# RockChip_RK3588 register map
Vendor: RockChip Electronics Co., Ltd.; Series: RK3588; File version: 0.1
Registers are 32-bit, read-write, no defined reset value unless marked. A register's access mark holds for its fields unless they carry their own. Offsets are from the block's base; [hi:lo] are bit positions; {n}, {i} and the like mark numbered series.

## IOC_EMMC
Base 0xFD5FD000
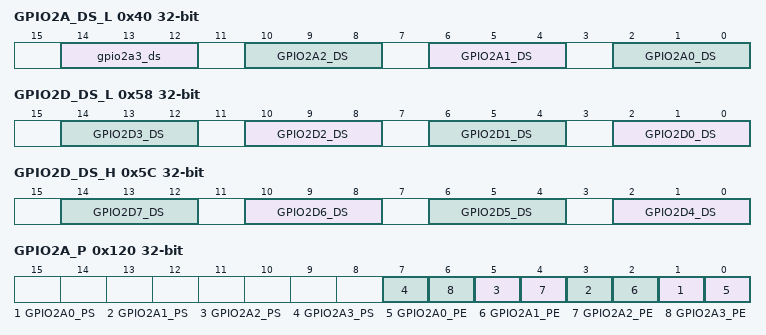
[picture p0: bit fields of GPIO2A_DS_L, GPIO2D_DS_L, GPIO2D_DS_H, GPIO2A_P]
0x40 GPIO2A_DS_L — GPIO2A Driver Strength Control Low bits
  [all] fields
    0=100OHM; 4=66OHM; 2=50OHM; 6=40OHM; 1=33OHM; 5=25OHM
  [14:12] gpio2a3_ds — GPIO2A3 DS control Driver Strength Selection
  [10:8] GPIO2A2_DS — GPIO2A2 DS control Driver Strength Selection
  [6:4] GPIO2A1_DS — GPIO2A1 DS control Driver Strength Selection
  [2:0] GPIO2A0_DS — GPIO2A0 DS control Driver Strength Selection
0x58 GPIO2D_DS_L — GPIO2D Driver Strength Control Low bits
  [all] fields
    0=100OHM; 4=66OHM; 2=50OHM; 6=40OHM; 1=33OHM; 5=25OHM
  [4n+2:4n] GPIO2D{n}_DS (n=0..3) — GPIO2D{n} DS control Driver Strength Selection
0x5C GPIO2D_DS_H — GPIO2D Driver Strength Control High bits
  [all] fields
    0=100OHM; 4=66OHM; 2=50OHM; 6=40OHM; 1=33OHM; 5=25OHM
  [4n-14:4n-16] GPIO2D{n}_DS (n=4..7) — GPIO2D{n} DS control Driver Strength Selection
0x120 GPIO2A_P — GPIO2A Pull-up/down Control
  [2n+1] GPIO2A{n}_PS (n=0..3) — GPIO2A{n} PS control Weak PU/PD Resistor Selection
    0=PD_SELECTION; 1=PU_SELECTION
  [2n] GPIO2A{n}_PE (n=0..3) — GPIO2A{n} PE control Active High Weak PU/PD Resistor Enable
    0=PU_PD_DISABLE; 1=PU_PD_ENABLE
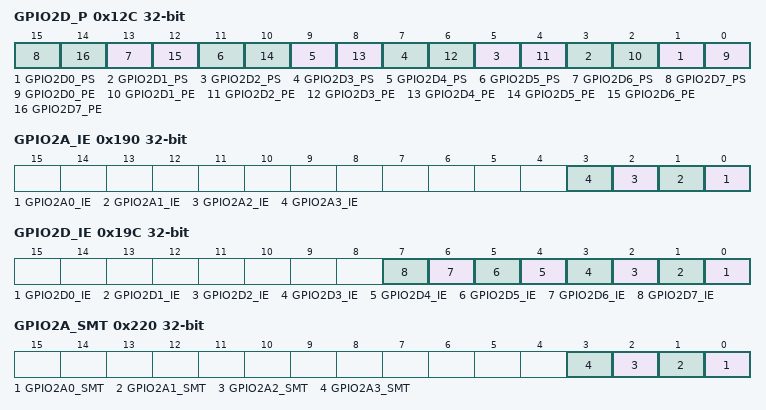
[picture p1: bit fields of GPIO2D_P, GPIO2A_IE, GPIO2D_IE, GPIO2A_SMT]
0x12C GPIO2D_P — GPIO2D Pull-up/down Control
  [2n+1] GPIO2D{n}_PS (n=0..7) — GPIO2D{n} PS control Weak PU/PD Resistor Selection
    0=PD_SELECTION; 1=PU_SELECTION
  [2n] GPIO2D{n}_PE (n=0..7) — GPIO2D{n} PE control Active High Weak PU/PD Resistor Enable
    0=PU_PD_DISABLE; 1=PU_PD_ENABLE
0x190 GPIO2A_IE — GPIO2A Input Enable Control
  [all] fields
    1=ENABLE; 0=DISABLE
  [n] GPIO2A{n}_IE (n=0..3) — GPIO2A{n} IE control Active High input buffer enable
0x19C GPIO2D_IE — GPIO2D Input Enable Control
  [all] fields
    1=ENABLE; 0=DISABLE
  [n] GPIO2D{n}_IE (n=0..7) — GPIO2D{n} IE control Active High input buffer enable
0x220 GPIO2A_SMT — GPIO2A Schmitt Trigger Control
  [all] fields
    0=CMOS; 1=SCHMITT_TRIGGER
  [n] GPIO2A{n}_SMT (n=0..3) — GPIO2A{n} SMT control CMOS/Schmitt Trigger Selection
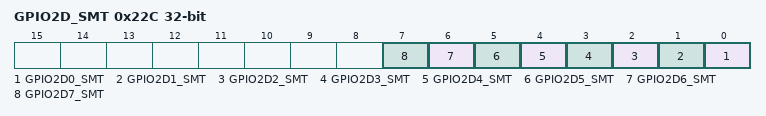
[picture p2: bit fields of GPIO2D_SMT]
0x22C GPIO2D_SMT — GPIO2D Schmitt Trigger Control
  [all] fields
    0=CMOS; 1=SCHMITT_TRIGGER
  [n] GPIO2D{n}_SMT (n=0..7) — GPIO2D{n} SMT control CMOS/Schmitt Trigger Selection
0x290 GPIO_PDIS — Auto Pull-up/down disable Control
  [0] EMMCIO_PULL_DIS
    1=DISABLE (disable VCCIO6 GPIO pull up/down when output enable)

## IOC_PMU1
Base 0xFD5F0000
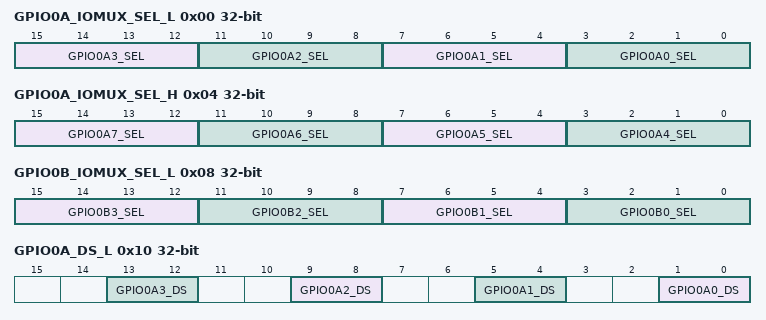
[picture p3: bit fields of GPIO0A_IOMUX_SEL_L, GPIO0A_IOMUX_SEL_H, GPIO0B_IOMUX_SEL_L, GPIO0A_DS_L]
0x00 GPIO0A_IOMUX_SEL_L — GPIO0A IOMUX Select Low bits
  [15:12] GPIO0A3_SEL
    0=GPIO; 1=PMIC_SLEEP2
  [11:8] GPIO0A2_SEL
    0=GPIO; 1=PMIC_SLEEP1; 2=TSADC_SHUT_M1
  [7:4] GPIO0A1_SEL
    0=GPIO; 1=TSADC_SHUT_ORG; 2=TSADC_SHUT
  [3:0] GPIO0A0_SEL
    0=GPIO; 1=REFCLK_OUT
0x04 GPIO0A_IOMUX_SEL_H — GPIO0A IOMUX Select High bits
  [15:12] GPIO0A7_SEL
    0=GPIO; 1=PMIC_INT_L
  [11:8] GPIO0A6_SEL
    0=GPIO; 1=SPI2_MOSI_M2; 2=I2C0_SDA_M0
  [7:4] GPIO0A5_SEL
    0=GPIO; 1=SPI2_CLK_M2; 2=SDMMC_PWREN; 3=PMU_DEBUG
  [3:0] GPIO0A4_SEL
    0=GPIO; 1=SDMMC_DET
0x08 GPIO0B_IOMUX_SEL_L — GPIO0B IOMUX Select Low bits
  [15:12] GPIO0B3_SEL
    0=GPIO; 1=SPI2_MISO_M2; 2=I2C0_SCL_M0
  [11:8] GPIO0B2_SEL
    0=GPIO; 1=CLK32K_IN; 2=CLK32K_OUT0
  [7:4] GPIO0B1_SEL
    0=GPIO; 1=SPI2_CS0_M2; 2=I2C1_SDA_M1; 3=PWM5_M0; 4=UART0_TX_M1
  [3:0] GPIO0B0_SEL
    0=GPIO; 1=SPI2_CS1_M2; 2=I2C1_SCL_M1; 4=UART0_RX_M1
0x10 GPIO0A_DS_L — GPIO0A Driver Strength Control Low bits
  [all] fields
    0=2_5MA_100OHM; 2=5MA_50OHM; 1=7_5MA_33OHM; 3=10MA_25OHM
  [4n+1:4n] GPIO0A{n}_DS (n=0..3) — GPIO0A{n} DS control Driver Strength Selection
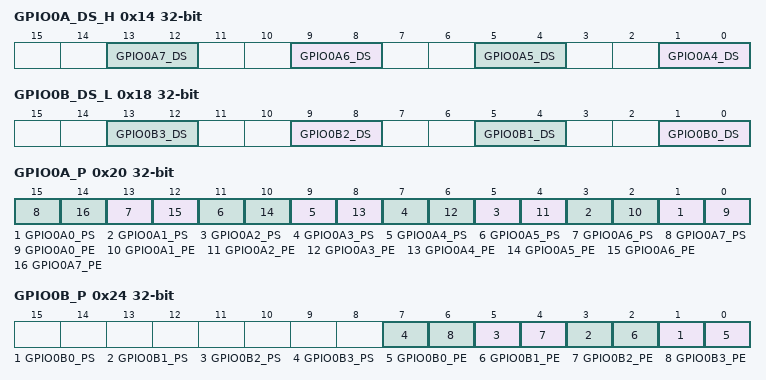
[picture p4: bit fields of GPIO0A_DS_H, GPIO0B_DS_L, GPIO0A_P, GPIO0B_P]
0x14 GPIO0A_DS_H — GPIO0A Driver Strength Control High bits
  [all] fields
    0=2_5MA_100OHM; 2=5MA_50OHM; 1=7_5MA_33OHM; 3=10MA_25OHM
  [4n-15:4n-16] GPIO0A{n}_DS (n=4..7) — GPIO0A{n} DS control Driver Strength Selection
0x18 GPIO0B_DS_L — GPIO0B Driver Strength Control Low bits
  [all] fields
    0=2_5MA_100OHM; 2=5MA_50OHM; 1=7_5MA_33OHM; 3=10MA_25OHM
  [4n+1:4n] GPIO0B{n}_DS (n=0..3) — GPIO0B{n} DS control Driver Strength Selection
0x20 GPIO0A_P — GPIO0A Pull-up/down Control
  [2n+1] GPIO0A{n}_PS (n=0..7) — GPIO0A{n} PS control Weak PU/PD Resistor Selection
    0=PD_SELECTION; 1=PU_SELECTION
  [2n] GPIO0A{n}_PE (n=0..7) — GPIO0A{n} PE control Active High Weak PU/PD Resistor Enable
    0=PU_PD_DISABLE; 1=PU_PD_ENABLE
0x24 GPIO0B_P — GPIO0B Pull-up/down Control
  [2n+1] GPIO0B{n}_PS (n=0..3) — GPIO0B{n} PS control Weak PU/PD Resistor Selection
    0=PD_SELECTION; 1=PU_SELECTION
  [2n] GPIO0B{n}_PE (n=0..3) — GPIO0B{n} PE control Active High Weak PU/PD Resistor Enable
    0=PU_PD_DISABLE; 1=PU_PD_ENABLE
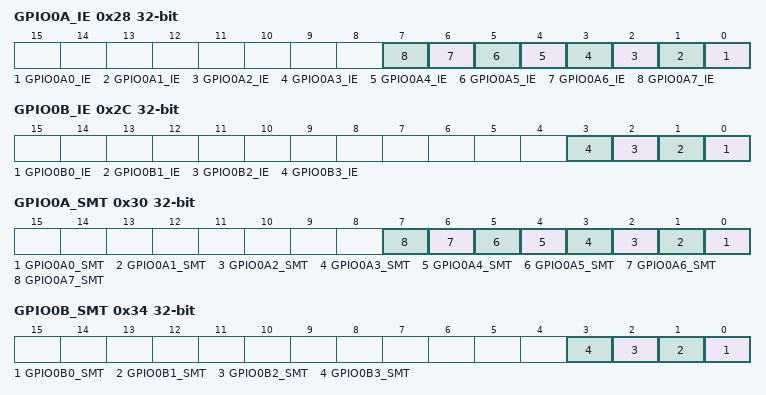
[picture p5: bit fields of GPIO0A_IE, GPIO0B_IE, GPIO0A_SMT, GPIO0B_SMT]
0x28 GPIO0A_IE — GPIO0A Input Enable Control
  [all] fields
    1=ENABLE; 0=DISABLE
  [n] GPIO0A{n}_IE (n=0..7) — GPIO0A{n} IE control Active High input buffer enable
0x2C GPIO0B_IE — GPIO0B Input Enable Control
  [all] fields
    1=ENABLE; 0=DISABLE
  [n] GPIO0B{n}_IE (n=0..3) — GPIO0B{n} IE control Active High input buffer enable
0x30 GPIO0A_SMT — GPIO0A Schmitt Trigger Control
  [all] fields
    0=CMOS; 1=SCHMITT_TRIGGER
  [n] GPIO0A{n}_SMT (n=0..7) — GPIO0A{n} SMT control CMOS/Schmitt Trigger Selection
0x34 GPIO0B_SMT — GPIO0B Schmitt Trigger Control
  [all] fields
    0=CMOS; 1=SCHMITT_TRIGGER
  [n] GPIO0B{n}_SMT (n=0..3) — GPIO0B{n} SMT control CMOS/Schmitt Trigger Selection
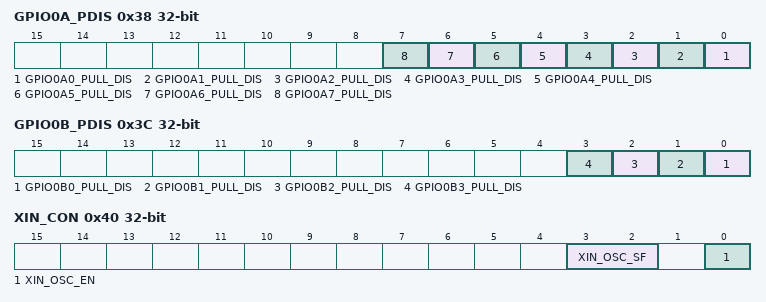
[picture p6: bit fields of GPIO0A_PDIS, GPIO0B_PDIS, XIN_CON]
0x38 GPIO0A_PDIS — GPIO0A Auto Pull-up/down disable Control
  [n] GPIO0A{n}_PULL_DIS (n=0..7)
    1=DISABLE (disable GPIO0A{n} pull up/down when output enable)
0x3C GPIO0B_PDIS — GPIO0B Auto Pull-up/down disable Control
  [n] GPIO0B{n}_PULL_DIS (n=0..3)
    1=DISABLE (disable GPIO0B{n} pull up/down when output enable)
0x40 XIN_CON — OSC control Register
  [3:2] XIN_OSC_SF — XIN OSC frequency pin selection
    0=1MHz_12MHz; 1=26_1MHz_36MHz; 2=12_1MHz_26MHz; 3=36_1MHz_52MHz
  [0] XIN_OSC_EN — XIN OSC enable
    1=ENABLE; 0=DISABLE
